# DEBUGSS_WRAP_SECAP_CFG_0_000700002600h register map
Vendor: Texas Instruments
Peripheral module from a debugger description file (folder AM275x).
Registers are 32-bit, read-write, reset 0x0 unless marked. A register's access mark holds for its fields unless they carry their own. Offsets are as the file gives them; lines under a group give offsets from that group; [hi:lo] are bit positions; {n}, {i} and the like mark numbered series; 'fields as' and 'values as' point back to an identical list; <NAME> marks a mode.

## secap_cfg_0
0x00 SECAP_CFG_0_TXDATA — Data value to send to security controller. APLLication specific
  [31:0] TX_DATA_REGISTER — Transmit Data. Writing this sets the TXDATAVAIL bit in the Transmit Control Register
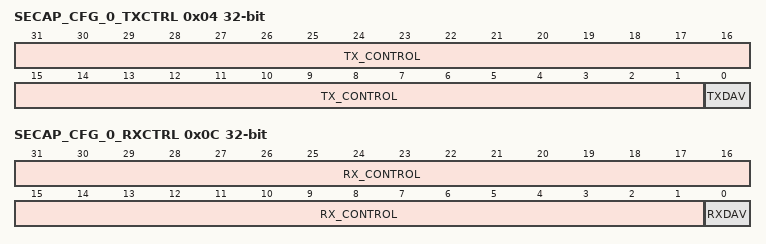
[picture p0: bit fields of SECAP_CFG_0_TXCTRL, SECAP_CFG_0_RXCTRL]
0x04 SECAP_CFG_0_TXCTRL access per field — Register to send control information to the Security Controller, Application specific
  [31:1] TX_CONTROL rw — 31 bits to send to security controller, Application specific
  [0] TXDAV ro — TX Data Available
0x08 SECAP_CFG_0_RXDATA — Data value from the security controller. Application specific
  [31:0] RX_DATA_REGISTER — Recieve Data. Writing this sets the RXDATAVAIL bit in the Recieve Control Register
0x0C SECAP_CFG_0_RXCTRL ro — Register to receive control information from the Security Controller
  [31:1] RX_CONTROL — 31 bits from the security controller, Application specific
  [0] RXDAV — TX Data Available
